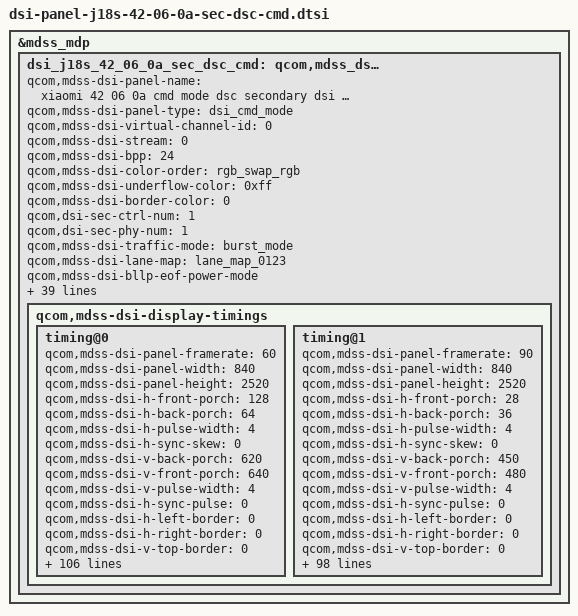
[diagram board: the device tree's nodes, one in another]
&mdss_mdp {
	dsi_j18s_42_06_0a_sec_dsc_cmd: qcom,mdss_dsi_j18s_42_06_0a_sec_dsc_cmd {
		qcom,mdss-dsi-panel-name = "xiaomi 42 06 0a cmd mode dsc secondary dsi panel";
		qcom,mdss-dsi-panel-type = "dsi_cmd_mode";
		qcom,mdss-dsi-virtual-channel-id = <0>;
		qcom,mdss-dsi-stream = <0>;
		qcom,mdss-dsi-bpp = <24>;
		qcom,mdss-dsi-color-order = "rgb_swap_rgb";
		qcom,mdss-dsi-underflow-color = <0xff>;
		qcom,mdss-dsi-border-color = <0>;

		qcom,dsi-sec-ctrl-num = <1>;
		qcom,dsi-sec-phy-num = <1>;

		qcom,mdss-dsi-traffic-mode = "burst_mode";
		qcom,mdss-dsi-lane-map = "lane_map_0123";
		qcom,mdss-dsi-bllp-eof-power-mode;
		qcom,mdss-dsi-bllp-power-mode;
		qcom,mdss-dsi-lane-0-state;
		qcom,mdss-dsi-lane-1-state;
		qcom,mdss-dsi-lane-2-state;
		qcom,mdss-dsi-lane-3-state;
		qcom,mdss-dsi-dma-trigger = "trigger_sw";
		qcom,mdss-dsi-mdp-trigger = "none";
		qcom,mdss-dsi-reset-sequence = <1 1>, <0 1>, <1 15>;
		qcom,mdss-pan-physical-width-dimension = <524>;
		qcom,mdss-pan-physical-height-dimension = <1572>;
		qcom,mdss-dsi-te-pin-select = <1>;
		qcom,mdss-dsi-wr-mem-start = <0x2c>;
		qcom,mdss-dsi-wr-mem-continue = <0x3c>;
		qcom,mdss-dsi-te-dcs-command = <1>;
		qcom,mdss-dsi-te-check-enable;
		qcom,mdss-dsi-te-using-te-pin;
		qcom,mdss-dsi-tx-eot-append;
		qcom,mdss-dsi-lp11-init;

		qcom,mdss-dsi-bl-inverted-dbv;

		qcom,mdss-dsi-panel-hdr-enabled;
		qcom,mdss-dsi-panel-hdr-color-primaries = <14500 15500 32000
			17000 15500 30000 8000 3000>;
		qcom,mdss-dsi-panel-peak-brightness = <4200000>;
		qcom,mdss-dsi-panel-blackness-level = <3230>;

		qcom,bl-update-flag = "delay_until_first_frame";

		qcom,mdss-dsi-display-timings {
			timing@0{
				qcom,mdss-dsi-panel-framerate = <60>;
				qcom,mdss-dsi-panel-width = <840>;
				qcom,mdss-dsi-panel-height = <2520>;
				qcom,mdss-dsi-h-front-porch = <128>;
				qcom,mdss-dsi-h-back-porch = <64>;
				qcom,mdss-dsi-h-pulse-width = <4>;
				qcom,mdss-dsi-h-sync-skew = <0>;
				qcom,mdss-dsi-v-back-porch = <620>;
				qcom,mdss-dsi-v-front-porch = <640>;
				qcom,mdss-dsi-v-pulse-width = <4>;
				qcom,mdss-dsi-h-sync-pulse = <0>;
				qcom,mdss-dsi-h-left-border = <0>;
				qcom,mdss-dsi-h-right-border = <0>;
				qcom,mdss-dsi-v-top-border = <0>;
				qcom,mdss-dsi-v-bottom-border = <0>;
				qcom,mdss-dsi-panel-clockrate = <650000000>;
				qcom,mdss-dsi-panel-jitter = <0x5 0x1>;
				qcom,mdss-mdp-transfer-time-us = <14000>;
				qcom,mdss-dsi-on-command = [
					15 00 00 00 00 00 02 FE 00
					15 00 00 00 00 00 02 FA 01
					15 00 00 00 00 00 02 FE 40
					15 00 00 00 00 00 02 82 34
					15 00 00 00 00 00 02 FE D0
					15 00 00 00 00 00 02 42 81
					15 00 00 00 00 00 02 49 01
					15 00 00 00 00 00 02 FE D2
					15 00 00 00 00 00 02 53 08
					15 00 00 00 00 00 02 72 07
					15 00 00 00 00 00 02 00 11
					15 00 00 00 00 00 02 01 ab
					15 00 00 00 00 00 02 02 30
					15 00 00 00 00 00 02 03 09
					15 00 00 00 00 00 02 04 d8
					15 00 00 00 00 00 02 05 03
					15 00 00 00 00 00 02 06 48
					15 00 00 00 00 00 02 07 02
					15 00 00 00 00 00 02 08 76
					15 00 00 00 00 00 02 09 03
					15 00 00 00 00 00 02 0a 48
					15 00 00 00 00 00 02 0b 02
					15 00 00 00 00 00 02 0c 00
					15 00 00 00 00 00 02 0d 20
					15 00 00 00 00 00 02 0e 49
					15 00 00 00 00 00 02 0f f6
					15 00 00 00 00 00 02 10 00
					15 00 00 00 00 00 02 11 0b
					15 00 00 00 00 00 02 12 0c
					15 00 00 00 00 00 02 13 00
					15 00 00 00 00 00 02 14 28
					15 00 00 00 00 00 02 15 00
					15 00 00 00 00 00 02 16 1b
					15 00 00 00 00 00 02 17 18
					15 00 00 00 00 00 02 18 00
					15 00 00 00 00 00 02 19 10
					15 00 00 00 00 00 02 1a f0
					15 00 00 00 00 00 02 1b 07
					15 00 00 00 00 00 02 1c 10
					15 00 00 00 00 00 02 1d 20
					15 00 00 00 00 00 02 1e 00
					15 00 00 00 00 00 02 1f 06
					15 00 00 00 00 00 02 20 0f
					15 00 00 00 00 00 02 21 0f
					15 00 00 00 00 00 02 22 33
					15 00 00 00 00 00 02 23 0e
					15 00 00 00 00 00 02 24 1c
					15 00 00 00 00 00 02 25 2a
					15 00 00 00 00 00 02 26 38
					15 00 00 00 00 00 02 27 46
					15 00 00 00 00 00 02 28 54
					15 00 00 00 00 00 02 29 62
					15 00 00 00 00 00 02 2a 69
					15 00 00 00 00 00 02 2b 70
					15 00 00 00 00 00 02 2d 77
					15 00 00 00 00 00 02 2f 79
					15 00 00 00 00 00 02 30 7b
					15 00 00 00 00 00 02 31 7d
					15 00 00 00 00 00 02 32 7e
					15 00 00 00 00 00 02 33 01
					15 00 00 00 00 00 02 34 02
					15 00 00 00 00 00 02 35 22
					15 00 00 00 00 00 02 36 00
					15 00 00 00 00 00 02 37 2a
					15 00 00 00 00 00 02 38 40
					15 00 00 00 00 00 02 39 2a
					15 00 00 00 00 00 02 3a be
					15 00 00 00 00 00 02 3b 3a
					15 00 00 00 00 00 02 3d fc
					15 00 00 00 00 00 02 3f 3a
					15 00 00 00 00 00 02 40 fa
					15 00 00 00 00 00 02 41 3a
					15 00 00 00 00 00 02 42 f8
					15 00 00 00 00 00 02 43 3b
					15 00 00 00 00 00 02 44 38
					15 00 00 00 00 00 02 45 3b
					15 00 00 00 00 00 02 46 78
					15 00 00 00 00 00 02 47 3b
					15 00 00 00 00 00 02 48 b6
					15 00 00 00 00 00 02 49 4b
					15 00 00 00 00 00 02 4a f6
					15 00 00 00 00 00 02 4b 4c
					15 00 00 00 00 00 02 4c 34
					15 00 00 00 00 00 02 4d 4c
					15 00 00 00 00 00 02 4e 74
					15 00 00 00 00 00 02 4f 5c
					15 00 00 00 00 00 02 50 74
					15 00 00 00 00 00 02 51 8c
					15 00 00 00 00 00 02 52 f4
					15 00 00 00 00 00 02 86 03
					15 00 00 00 00 00 02 87 48
					15 00 00 00 00 00 02 88 00
					15 00 00 00 00 00 02 89 00
					15 00 00 00 00 00 02 8a 00
					15 00 00 00 00 00 02 8b 00
					15 00 00 00 00 00 02 8c 00
					15 00 00 00 00 00 02 8d 00
					15 01 00 00 00 00 02 8e 80
					15 00 00 00 00 00 02 FE E0
					15 00 00 00 00 00 02 E7 00
					/* switch to 60fps */
					15 00 00 00 00 00 02 FE D0
					/*60fps setting*/
					15 00 00 00 00 00 02 70 81
					15 00 00 00 00 00 02 FE 60
					/*extend pulse off*/
					15 00 00 00 00 00 02 C3 00
					15 00 00 00 00 00 02 FE 74
					/*gamma mapping*/
					15 00 00 00 00 00 02 0E FF
					15 00 00 00 00 00 02 0F 00
					15 00 00 00 00 00 02 10 14
					15 00 00 00 00 00 02 11 14
					15 00 00 00 00 00 02 12 13
					15 00 00 00 00 00 02 13 12
					15 00 00 00 00 00 02 14 11
					15 00 00 00 00 00 02 15 10
					15 00 00 00 00 00 02 16 0F
					15 00 00 00 00 00 02 17 0E
					15 00 00 00 00 00 02 18 0D
					15 00 00 00 00 00 02 19 0C
					/*fix flicker issue after phone power up*/
					15 00 00 00 00 00 02 FE 70
					15 00 00 00 00 00 02 30 FF
					15 00 00 00 00 00 02 31 FF
					15 00 00 00 00 00 02 32 FF
					15 00 00 00 00 00 02 33 FF
					15 00 00 00 00 00 02 34 FF
					15 00 00 00 00 00 02 FE 40
					15 00 00 00 00 00 02 1B 20
					15 00 00 00 00 00 02 1C 02
					15 00 00 00 00 00 02 FE 70
					15 00 00 00 00 00 02 35 03
					/* fix AOD flicker issue*/
					15 00 00 00 00 00 02 FE 40
					15 00 00 00 00 00 02 08 13
					15 00 00 00 00 00 02 09 15
					15 00 00 00 00 00 02 6B 20
					15 00 00 00 00 00 02 3D 52
					/* OSC learning*/
					15 00 00 00 00 00 02 FE D0
					15 00 00 00 00 00 02 8F 00
					15 00 00 00 00 00 02 90 AD
					15 00 00 00 00 00 02 91 01
					15 00 00 00 00 00 02 92 2C
					15 00 00 00 00 00 02 93 00
					15 00 00 00 00 00 02 94 05
					15 00 00 00 00 00 02 95 0C
					15 00 00 00 00 00 02 8C 83
					15 00 00 00 00 00 02 FE 00
					15 00 00 00 00 00 02 5E 01
					15 00 00 00 00 00 02 C2 08
					15 00 00 00 00 00 02 35 00
					39 01 00 00 00 00 03 51 00 00
					05 01 00 00 60 00 02 11 00/* Sleep Out */
					05 01 00 00 00 00 02 29 00];/* Display On */
				qcom,mdss-dsi-off-command = [
					05 01 00 00 22 00 02 28 00
					05 01 00 00 11 00 02 10 00];
				qcom,mdss-dsi-on-command-state = "dsi_lp_mode";
				qcom,mdss-dsi-off-command-state = "dsi_lp_mode";

				qcom,mdss-dsi-timing-switch-command = [
					/* switch to 60fps */
					15 00 00 00 00 00 02 FE D0
					/*60fps setting*/
					15 00 00 00 00 00 02 70 81
					15 00 00 00 00 00 02 FE 60
					/*extend pulse off*/
					15 00 00 00 00 00 02 C3 00
					15 00 00 00 00 00 02 FE 74
					/*gamma mapping*/
					15 00 00 00 00 00 02 0E FF
					15 00 00 00 00 00 02 0F 00
					15 00 00 00 00 00 02 10 14
					15 00 00 00 00 00 02 11 14
					15 00 00 00 00 00 02 12 13
					15 00 00 00 00 00 02 13 12
					15 00 00 00 00 00 02 14 11
					15 00 00 00 00 00 02 15 10
					15 00 00 00 00 00 02 16 0F
					15 00 00 00 00 00 02 17 0E
					15 00 00 00 00 00 02 18 0D
					15 00 00 00 00 00 02 19 0C
					/* OSC learning*/
					15 00 00 00 00 00 02 FE D0
					15 00 00 00 00 00 02 8F 00
					15 00 00 00 00 00 02 90 AD
					15 00 00 00 00 00 02 91 01
					15 00 00 00 00 00 02 92 2C
					15 00 00 00 00 00 02 93 00
					15 00 00 00 00 00 02 94 05
					15 00 00 00 00 00 02 95 0C
					15 00 00 00 00 00 02 8C 83
					15 01 00 00 00 00 02 FE 00];
				qcom,mdss-dsi-timing-switch-command-state = "dsi_lp_mode";

				qcom,mdss-dsi-lp1-command = [
					/*extend pulse off*/
					15 00 00 00 00 00 02 FE 60
					15 00 00 00 00 00 02 C3 00
					/* enter AOD*/
					15 00 00 00 00 00 02 FE 00
					15 00 00 00 00 00 02 39 00
					/* fix AOD flicker issue*/
					15 00 00 00 00 00 02 FE 72
					15 00 00 00 00 00 02 49 40
					15 00 00 00 00 00 02 FE 60
					15 00 00 00 00 00 02 CE 10
					15 00 00 00 00 00 02 E2 10
					15 01 00 00 00 00 02 FE 00];
				qcom,mdss-dsi-lp1-command-state = "dsi_lp_mode";

				qcom,mdss-dsi-nolp-command = [
					/* exit AOD*/
					15 00 00 00 00 00 02 FE 00
					15 00 00 00 00 00 02 38 00
					/* fix AOD flicker issue*/
					15 00 00 00 00 00 02 FE 72
					15 00 00 00 00 00 02 49 00
					15 00 00 00 00 00 02 FE 60
					15 00 00 00 00 00 02 CE 1D
					15 00 00 00 00 00 02 E2 1D
					/* extend pulse off */
					15 00 00 00 00 00 02 C3 00
					/* OSC learning*/
					15 00 00 00 00 00 02 FE D0
					15 00 00 00 00 00 02 8F 00
					15 00 00 00 00 00 02 90 AD
					15 00 00 00 00 00 02 91 01
					15 00 00 00 00 00 02 92 2C
					15 00 00 00 00 00 02 93 00
					15 00 00 00 00 00 02 94 05
					15 00 00 00 00 00 02 95 0C
					15 00 00 00 00 00 02 8C 83
					15 01 00 00 00 00 02 FE 00];
				qcom,mdss-dsi-nolp-command-state = "dsi_lp_mode";

				qcom,compression-mode = "dsc";
				qcom,mdss-dsc-slice-height = <630>;
				qcom,mdss-dsc-slice-width = <840>;
				qcom,mdss-dsc-slice-per-pkt = <2>;
				qcom,mdss-dsc-bit-per-component = <10>;
				qcom,mdss-dsc-bit-per-pixel = <8>;
				qcom,mdss-dsc-block-prediction-enable;
			};
			timing@1{
				qcom,mdss-dsi-panel-framerate = <90>;
				qcom,mdss-dsi-panel-width = <840>;
				qcom,mdss-dsi-panel-height = <2520>;
				qcom,mdss-dsi-h-front-porch = <28>;
				qcom,mdss-dsi-h-back-porch = <36>;
				qcom,mdss-dsi-h-pulse-width = <4>;
				qcom,mdss-dsi-h-sync-skew = <0>;
				qcom,mdss-dsi-v-back-porch = <450>;
				qcom,mdss-dsi-v-front-porch = <480>;
				qcom,mdss-dsi-v-pulse-width = <4>;
				qcom,mdss-dsi-h-sync-pulse = <0>;
				qcom,mdss-dsi-h-left-border = <0>;
				qcom,mdss-dsi-h-right-border = <0>;
				qcom,mdss-dsi-v-top-border = <0>;
				qcom,mdss-dsi-v-bottom-border = <0>;
				qcom,mdss-dsi-panel-clockrate = <650000000>;
				qcom,mdss-dsi-panel-jitter = <0x5 0x1>;
				qcom,mdss-mdp-transfer-time-us = <9500>;
				qcom,mdss-dsi-on-command = [
					15 00 00 00 00 00 02 FE 00
					15 00 00 00 00 00 02 FA 01
					15 00 00 00 00 00 02 FE 40
					15 00 00 00 00 00 02 82 34
					15 00 00 00 00 00 02 FE D0
					15 00 00 00 00 00 02 42 81
					15 00 00 00 00 00 02 49 01
					15 00 00 00 00 00 02 FE D2
					15 00 00 00 00 00 02 53 08
					15 00 00 00 00 00 02 72 07
					15 00 00 00 00 00 02 00 11
					15 00 00 00 00 00 02 01 ab
					15 00 00 00 00 00 02 02 30
					15 00 00 00 00 00 02 03 09
					15 00 00 00 00 00 02 04 d8
					15 00 00 00 00 00 02 05 03
					15 00 00 00 00 00 02 06 48
					15 00 00 00 00 00 02 07 02
					15 00 00 00 00 00 02 08 76
					15 00 00 00 00 00 02 09 03
					15 00 00 00 00 00 02 0a 48
					15 00 00 00 00 00 02 0b 02
					15 00 00 00 00 00 02 0c 00
					15 00 00 00 00 00 02 0d 20
					15 00 00 00 00 00 02 0e 49
					15 00 00 00 00 00 02 0f f6
					15 00 00 00 00 00 02 10 00
					15 00 00 00 00 00 02 11 0b
					15 00 00 00 00 00 02 12 0c
					15 00 00 00 00 00 02 13 00
					15 00 00 00 00 00 02 14 28
					15 00 00 00 00 00 02 15 00
					15 00 00 00 00 00 02 16 1b
					15 00 00 00 00 00 02 17 18
					15 00 00 00 00 00 02 18 00
					15 00 00 00 00 00 02 19 10
					15 00 00 00 00 00 02 1a f0
					15 00 00 00 00 00 02 1b 07
					15 00 00 00 00 00 02 1c 10
					15 00 00 00 00 00 02 1d 20
					15 00 00 00 00 00 02 1e 00
					15 00 00 00 00 00 02 1f 06
					15 00 00 00 00 00 02 20 0f
					15 00 00 00 00 00 02 21 0f
					15 00 00 00 00 00 02 22 33
					15 00 00 00 00 00 02 23 0e
					15 00 00 00 00 00 02 24 1c
					15 00 00 00 00 00 02 25 2a
					15 00 00 00 00 00 02 26 38
					15 00 00 00 00 00 02 27 46
					15 00 00 00 00 00 02 28 54
					15 00 00 00 00 00 02 29 62
					15 00 00 00 00 00 02 2a 69
					15 00 00 00 00 00 02 2b 70
					15 00 00 00 00 00 02 2d 77
					15 00 00 00 00 00 02 2f 79
					15 00 00 00 00 00 02 30 7b
					15 00 00 00 00 00 02 31 7d
					15 00 00 00 00 00 02 32 7e
					15 00 00 00 00 00 02 33 01
					15 00 00 00 00 00 02 34 02
					15 00 00 00 00 00 02 35 22
					15 00 00 00 00 00 02 36 00
					15 00 00 00 00 00 02 37 2a
					15 00 00 00 00 00 02 38 40
					15 00 00 00 00 00 02 39 2a
					15 00 00 00 00 00 02 3a be
					15 00 00 00 00 00 02 3b 3a
					15 00 00 00 00 00 02 3d fc
					15 00 00 00 00 00 02 3f 3a
					15 00 00 00 00 00 02 40 fa
					15 00 00 00 00 00 02 41 3a
					15 00 00 00 00 00 02 42 f8
					15 00 00 00 00 00 02 43 3b
					15 00 00 00 00 00 02 44 38
					15 00 00 00 00 00 02 45 3b
					15 00 00 00 00 00 02 46 78
					15 00 00 00 00 00 02 47 3b
					15 00 00 00 00 00 02 48 b6
					15 00 00 00 00 00 02 49 4b
					15 00 00 00 00 00 02 4a f6
					15 00 00 00 00 00 02 4b 4c
					15 00 00 00 00 00 02 4c 34
					15 00 00 00 00 00 02 4d 4c
					15 00 00 00 00 00 02 4e 74
					15 00 00 00 00 00 02 4f 5c
					15 00 00 00 00 00 02 50 74
					15 00 00 00 00 00 02 51 8c
					15 00 00 00 00 00 02 52 f4
					15 00 00 00 00 00 02 86 03
					15 00 00 00 00 00 02 87 48
					15 00 00 00 00 00 02 88 00
					15 00 00 00 00 00 02 89 00
					15 00 00 00 00 00 02 8a 00
					15 00 00 00 00 00 02 8b 00
					15 00 00 00 00 00 02 8c 00
					15 00 00 00 00 00 02 8d 00
					15 01 00 00 00 00 02 8e 80
					15 00 00 00 00 00 02 FE E0
					15 00 00 00 00 00 02 E7 00
					/*fix flicker issue after phone power up*/
					15 00 00 00 00 00 02 FE 70
					15 00 00 00 00 00 02 30 FF
					15 00 00 00 00 00 02 31 FF
					15 00 00 00 00 00 02 32 FF
					15 00 00 00 00 00 02 33 FF
					15 00 00 00 00 00 02 34 FF
					15 00 00 00 00 00 02 FE 40
					15 00 00 00 00 00 02 1B 20
					15 00 00 00 00 00 02 1C 02
					15 00 00 00 00 00 02 FE 70
					15 00 00 00 00 00 02 35 03
					/* fix AOD flicker issue*/
					15 00 00 00 00 00 02 FE 40
					15 00 00 00 00 00 02 6B 20
					15 00 00 00 00 00 02 3D 52
					15 00 00 00 00 00 02 08 13
					15 00 00 00 00 00 02 09 15
					/* OSC learning*/
					15 00 00 00 00 00 02 FE D0
					15 00 00 00 00 00 02 8F 02
					15 00 00 00 00 00 02 90 49
					15 00 00 00 00 00 02 91 03
					15 00 00 00 00 00 02 92 E8
					15 00 00 00 00 00 02 93 00
					15 00 00 00 00 00 02 94 05
					15 00 00 00 00 00 02 95 05
					15 00 00 00 00 00 02 8C 83
					15 00 00 00 00 00 02 FE 00
					15 00 00 00 00 00 02 5E 01
					15 00 00 00 00 00 02 C2 08
					15 00 00 00 00 00 02 35 00
					39 01 00 00 00 00 03 51 00 00
					05 01 00 00 60 00 02 11 00/* Sleep Out */
					05 01 00 00 00 00 02 29 00];/* Display On */
				qcom,mdss-dsi-off-command = [
					05 01 00 00 22 00 02 28 00
					05 01 00 00 11 00 02 10 00];
				qcom,mdss-dsi-on-command-state = "dsi_lp_mode";
				qcom,mdss-dsi-off-command-state = "dsi_lp_mode";

				qcom,mdss-dsi-timing-switch-command = [
					/* switch to 90fps */
					15 00 00 00 00 00 02 FE D0
					/*90fps setting*/
					15 00 00 00 00 00 02 70 01
					15 00 00 00 00 00 02 FE 74
					/*gamma mapping*/
					15 00 00 00 00 00 02 0E FF
					15 00 00 00 00 00 02 0F 00
					15 00 00 00 00 00 02 10 09
					15 00 00 00 00 00 02 11 09
					15 00 00 00 00 00 02 12 08
					15 00 00 00 00 00 02 13 07
					15 00 00 00 00 00 02 14 06
					15 00 00 00 00 00 02 15 05
					15 00 00 00 00 00 02 16 04
					15 00 00 00 00 00 02 17 03
					15 00 00 00 00 00 02 18 02
					15 00 00 00 00 00 02 19 01
					/* OSC learning*/
					15 00 00 00 00 00 02 FE D0
					15 00 00 00 00 00 02 8F 02
					15 00 00 00 00 00 02 90 49
					15 00 00 00 00 00 02 91 03
					15 00 00 00 00 00 02 92 E8
					15 00 00 00 00 00 02 93 00
					15 00 00 00 00 00 02 94 05
					15 00 00 00 00 00 02 95 05
					15 00 00 00 00 00 02 8C 83
					15 01 00 00 00 00 02 FE 00];
				qcom,mdss-dsi-timing-switch-command-state = "dsi_lp_mode";

				qcom,mdss-dsi-lp1-command = [
					/* switch to 60fps */
					15 00 00 00 00 00 02 FE D0
					15 00 00 00 00 00 02 70 81
					15 00 00 00 00 00 02 FE 60
					15 00 00 00 00 00 02 C3 00
					15 00 00 00 00 00 02 FE 74
					/*gamma mapping*/
					15 00 00 00 00 00 02 0E FF
					15 00 00 00 00 00 02 0F 00
					15 00 00 00 00 00 02 10 14
					15 00 00 00 00 00 02 11 14
					15 00 00 00 00 00 02 12 13
					15 00 00 00 00 00 02 13 12
					15 00 00 00 00 00 02 14 11
					15 00 00 00 00 00 02 15 10
					15 00 00 00 00 00 02 16 0F
					15 00 00 00 00 00 02 17 0E
					15 00 00 00 00 00 02 18 0D
					15 00 00 00 00 00 02 19 0C
					/* enter AOD*/
					15 00 00 00 00 00 02 FE 00
					15 00 00 00 00 00 02 39 00
					/* fix AOD flicker issue*/
					15 00 00 00 00 00 02 FE 72
					15 00 00 00 00 00 02 49 40
					15 00 00 00 00 00 02 FE 60
					15 00 00 00 00 00 02 CE 10
					15 00 00 00 00 00 02 E2 10
					15 01 00 00 00 00 02 FE 00];
				qcom,mdss-dsi-lp1-command-state = "dsi_lp_mode";

				qcom,mdss-dsi-nolp-command = [
					/* exit AOD*/
					15 00 00 00 00 00 02 FE 00
					15 00 00 00 00 00 02 38 00
					/* fix AOD flicker issue*/
					15 00 00 00 00 00 02 FE 72
					15 00 00 00 00 00 02 49 00
					15 00 00 00 00 00 02 FE 60
					15 00 00 00 00 00 02 CE 1D
					15 00 00 00 00 00 02 E2 1D
					/* switch to 90fps */
					15 00 00 00 00 00 02 FE D0
					/*90fps setting*/
					15 00 00 00 00 00 02 70 01
					15 00 00 00 00 00 02 FE 60
					15 00 00 00 00 00 02 C3 08
					15 00 00 00 00 00 02 FE 74
					/*gamma mapping*/
					15 00 00 00 00 00 02 0E FF
					15 00 00 00 00 00 02 0F 00
					15 00 00 00 00 00 02 10 09
					15 00 00 00 00 00 02 11 09
					15 00 00 00 00 00 02 12 08
					15 00 00 00 00 00 02 13 07
					15 00 00 00 00 00 02 14 06
					15 00 00 00 00 00 02 15 05
					15 00 00 00 00 00 02 16 04
					15 00 00 00 00 00 02 17 03
					15 00 00 00 00 00 02 18 02
					15 00 00 00 00 00 02 19 01
					/* OSC learning*/
					15 00 00 00 00 00 02 FE D0
					15 00 00 00 00 00 02 8F 02
					15 00 00 00 00 00 02 90 49
					15 00 00 00 00 00 02 91 03
					15 00 00 00 00 00 02 92 E8
					15 00 00 00 00 00 02 93 00
					15 00 00 00 00 00 02 94 05
					15 00 00 00 00 00 02 95 05
					15 00 00 00 00 00 02 8C 83
					15 01 00 00 00 00 02 FE 00];
				qcom,mdss-dsi-nolp-command-state = "dsi_lp_mode";

				qcom,compression-mode = "dsc";
				qcom,mdss-dsc-slice-height = <630>;
				qcom,mdss-dsc-slice-width = <840>;
				qcom,mdss-dsc-slice-per-pkt = <2>;
				qcom,mdss-dsc-bit-per-component = <10>;
				qcom,mdss-dsc-bit-per-pixel = <8>;
				qcom,mdss-dsc-block-prediction-enable;
			};
		};
	};
};

&dsi_j18s_42_06_0a_sec_dsc_cmd {
	mi,esd-err-irq-gpio = <&tlmm 75 0x2001>;

	mi,aod-nolp-command-enabled;
	mi,aod-bl-51ctl-flag;
	mi,fp-display-on-optimize-flag;
	mi,mdss-dsi-panel-bl-dfps-enabled;
	mi,mdss-dsi-panel-bl-dfps-switch-threshold = <0x3B8>;

	mi,mdss-dsi-panel-bl-demura-enabled;
	mi,mdss-dsi-panel-bl-demura = <10 38 95 285 951 4095>;

	mi,mdss-dsi-panel-dc-type = <0>;
	mi,mdss-dsi-panel-dc-threshold = <0x11D>;
	mi,max-brightness-clone = <8191>;
	mi,panel-on-dimming-delay = <120>;

	qcom,mdss-dsi-display-timings {
		timing@0{
			mi,mdss-dsi-timing-switch-command = [
				/* switch to 60fps */
				15 00 00 00 00 00 02 FE D0
				/*60fps setting*/
				15 00 00 00 00 00 02 70 81
				15 00 00 00 00 00 02 FE 60
				/*extend pulse on*/
				15 00 00 00 00 00 02 C3 08
				15 00 00 00 00 00 02 FE 74
				/*gamma mapping*/
				15 00 00 00 00 00 02 0E FF
				15 00 00 00 00 00 02 0F 00
				15 00 00 00 00 00 02 10 14
				15 00 00 00 00 00 02 11 14
				15 00 00 00 00 00 02 12 13
				15 00 00 00 00 00 02 13 12
				15 00 00 00 00 00 02 14 11
				15 00 00 00 00 00 02 15 10
				15 00 00 00 00 00 02 16 0F
				15 00 00 00 00 00 02 17 0E
				15 00 00 00 00 00 02 18 0D
				15 00 00 00 00 00 02 19 0C
				/* OSC learning*/
				15 00 00 00 00 00 02 FE D0
				15 00 00 00 00 00 02 8F 00
				15 00 00 00 00 00 02 90 AD
				15 00 00 00 00 00 02 91 01
				15 00 00 00 00 00 02 92 2C
				15 00 00 00 00 00 02 93 00
				15 00 00 00 00 00 02 94 05
				15 00 00 00 00 00 02 95 0C
				15 00 00 00 00 00 02 8C 83
				15 01 00 00 00 00 02 FE 00];
			mi,mdss-dsi-timing-switch-command-state = "dsi_lp_mode";

			mi,mdss-dsi-timing-switch-dc-lbm-command = [
				/* switch to 60fps */
				15 00 00 00 00 00 02 FE D0
				15 00 00 00 00 00 02 70 81
				/*gamma mapping*/
				15 00 00 00 00 00 02 FE 74
				15 00 00 00 00 00 02 0E 80
				15 00 00 00 00 00 02 0F 00
				15 00 00 00 00 00 02 10 0D
				15 00 00 00 00 00 02 11 00
				15 00 00 00 00 00 02 12 00
				15 00 00 00 00 00 02 13 00
				15 00 00 00 00 00 02 14 00
				15 00 00 00 00 00 02 15 00
				15 00 00 00 00 00 02 16 00
				15 00 00 00 00 00 02 17 00
				15 00 00 00 00 00 02 18 0D
				15 00 00 00 00 00 02 19 0C
				15 00 00 00 00 00 02 FE 40
				15 00 00 00 00 00 02 46 39
				15 00 00 00 00 00 02 FE 60
				15 00 00 00 00 00 02 C3 00
				/* OSC learning*/
				15 00 00 00 00 00 02 FE D0
				15 00 00 00 00 00 02 8F 00
				15 00 00 00 00 00 02 90 AD
				15 00 00 00 00 00 02 91 01
				15 00 00 00 00 00 02 92 2C
				15 00 00 00 00 00 02 93 00
				15 00 00 00 00 00 02 94 05
				15 00 00 00 00 00 02 95 0C
				15 00 00 00 00 00 02 8C 83
				15 01 00 00 00 00 02 FE 00];
			mi,mdss-dsi-timing-switch-dc-lbm-command-state = "dsi_lp_mode";

			mi,mdss-dsi-timing-switch-dc-hbm-command = [
				/* switch to 60fps */
				15 00 00 00 00 00 02 FE D0
				15 00 00 00 00 00 02 70 81
				/*gamma mapping*/
				15 00 00 00 00 00 02 FE 74
				15 00 00 00 00 00 02 0E 80
				15 00 00 00 00 00 02 0F 00
				15 00 00 00 00 00 02 10 0D
				15 00 00 00 00 00 02 11 00
				15 00 00 00 00 00 02 12 00
				15 00 00 00 00 00 02 13 00
				15 00 00 00 00 00 02 14 00
				15 00 00 00 00 00 02 15 00
				15 00 00 00 00 00 02 16 00
				15 00 00 00 00 00 02 17 00
				15 00 00 00 00 00 02 18 0D
				15 00 00 00 00 00 02 19 0C
				15 00 00 00 00 00 02 FE 40
				15 00 00 00 00 00 02 46 3E
				/* OSC learning*/
				15 00 00 00 00 00 02 FE D0
				15 00 00 00 00 00 02 8F 00
				15 00 00 00 00 00 02 90 AD
				15 00 00 00 00 00 02 91 01
				15 00 00 00 00 00 02 92 2C
				15 00 00 00 00 00 02 93 00
				15 00 00 00 00 00 02 94 05
				15 00 00 00 00 00 02 95 0C
				15 00 00 00 00 00 02 8C 83
				15 01 00 00 00 00 02 FE 00];
			mi,mdss-dsi-timing-switch-dc-hbm-command-state = "dsi_lp_mode";

			mi,mdss-dsi-bl-extpulse-on-command = [
				/*extend pulse on*/
				15 00 00 00 00 00 02 FE 60
				15 00 00 00 00 00 02 C3 08
				15 01 00 00 00 00 02 FE 00];
			mi,mdss-dsi-bl-extpulse-on-command-state = "dsi_lp_mode";

			mi,mdss-dsi-bl-extpulse-off-command = [
				/*extend pulse off*/
				15 00 00 00 00 00 02 FE 60
				15 00 00 00 00 00 02 C3 00
				15 01 00 00 00 00 02 FE 00];
			mi,mdss-dsi-bl-extpulse-off-command-state = "dsi_lp_mode";

			mi,mdss-dsi-vi-lbm-command = [
				/*extend pulse off*/
				15 00 00 00 00 00 02 FE 40
				15 00 00 00 00 00 02 46 39
				15 01 00 00 00 00 02 FE 00];
			mi,mdss-dsi-vi-lbm-command-state = "dsi_lp_mode";

			mi,mdss-dsi-vi-hbm-command = [
				/*extend pulse off*/
				15 00 00 00 00 00 02 FE 40
				15 00 00 00 00 00 02 46 3E
				15 01 00 00 00 00 02 FE 00];
			mi,mdss-dsi-vi-hbm-command-state = "dsi_lp_mode";

			mi,mdss-dsi-dc-on-command = [
				15 00 00 00 00 00 02 FE 74
				15 00 00 00 00 00 02 00 00
				15 00 00 00 00 00 02 01 00
				15 00 00 00 00 00 02 02 00
				15 00 00 00 00 00 02 03 70
				15 00 00 00 00 00 02 04 0F
				15 00 00 00 00 00 02 05 00
				15 00 00 00 00 00 02 06 00
				15 00 00 00 00 00 02 07 00
				15 00 00 00 00 00 02 08 00
				15 00 00 00 00 00 02 09 00
				15 00 00 00 00 00 02 0A 00
				15 00 00 00 00 00 02 0B 00
				15 00 00 00 00 00 02 0C FF
				15 00 00 00 00 00 02 0D FF
				15 00 00 00 00 00 02 0E 80
				15 00 00 00 00 00 02 0F 00
				15 00 00 00 00 00 02 10 0D
				15 00 00 00 00 00 02 11 00
				15 00 00 00 00 00 02 12 00
				15 00 00 00 00 00 02 13 00
				15 00 00 00 00 00 02 14 00
				15 00 00 00 00 00 02 15 00
				15 00 00 00 00 00 02 16 00
				15 00 00 00 00 00 02 17 00
				15 00 00 00 00 00 02 18 0D
				15 00 00 00 00 00 02 19 0C
				15 00 00 00 00 00 02 22 80
				15 00 00 00 00 00 02 43 80
				15 00 00 00 00 00 02 44 00
				15 00 00 00 00 00 02 45 FF
				15 00 00 00 00 00 02 46 FF
				15 00 00 00 00 00 02 47 FF
				15 00 00 00 00 00 02 48 FF
				15 00 00 00 00 00 02 49 FF
				15 00 00 00 00 00 02 4A FF
				15 00 00 00 00 00 02 4B FF
				15 00 00 00 00 00 02 4C FF
				15 00 00 00 00 00 02 4D FF
				15 00 00 00 00 00 02 4E FF
				15 00 00 00 00 00 02 4F FF
				15 00 00 00 00 00 02 50 FF
				15 00 00 00 00 00 02 51 FF
				15 00 00 00 00 00 02 52 FF
				15 00 00 00 00 00 02 53 FF
				15 00 00 00 00 00 02 61 80
				15 00 00 00 00 00 02 FE 20
				15 00 00 00 00 00 02 B8 08
				15 00 00 00 00 00 02 B9 08
				15 00 00 00 00 00 02 BA 08
				15 00 00 00 00 00 02 FE 40
				15 01 00 00 22 00 02 46 39
				15 00 00 00 00 00 02 FE 60
				15 00 00 00 00 00 02 C3 00
				15 01 00 00 00 00 02 FE 00];
			mi,mdss-dsi-dc-on-command-state = "dsi_lp_mode";

			mi,mdss-dsi-dc-on-hbm-command = [
				15 00 00 00 00 00 02 FE 74
				15 00 00 00 00 00 02 00 00
				15 00 00 00 00 00 02 01 00
				15 00 00 00 00 00 02 02 00
				15 00 00 00 00 00 02 03 70
				15 00 00 00 00 00 02 04 0F
				15 00 00 00 00 00 02 05 00
				15 00 00 00 00 00 02 06 00
				15 00 00 00 00 00 02 07 00
				15 00 00 00 00 00 02 08 00
				15 00 00 00 00 00 02 09 00
				15 00 00 00 00 00 02 0A 00
				15 00 00 00 00 00 02 0B 00
				15 00 00 00 00 00 02 0C FF
				15 00 00 00 00 00 02 0D FF
				15 00 00 00 00 00 02 0E 80
				15 00 00 00 00 00 02 0F 00
				15 00 00 00 00 00 02 10 0D
				15 00 00 00 00 00 02 11 00
				15 00 00 00 00 00 02 12 00
				15 00 00 00 00 00 02 13 00
				15 00 00 00 00 00 02 14 00
				15 00 00 00 00 00 02 15 00
				15 00 00 00 00 00 02 16 00
				15 00 00 00 00 00 02 17 00
				15 00 00 00 00 00 02 18 0D
				15 00 00 00 00 00 02 19 0C
				15 00 00 00 00 00 02 22 80
				15 00 00 00 00 00 02 43 80
				15 00 00 00 00 00 02 44 00
				15 00 00 00 00 00 02 45 FF
				15 00 00 00 00 00 02 46 FF
				15 00 00 00 00 00 02 47 FF
				15 00 00 00 00 00 02 48 FF
				15 00 00 00 00 00 02 49 FF
				15 00 00 00 00 00 02 4A FF
				15 00 00 00 00 00 02 4B FF
				15 00 00 00 00 00 02 4C FF
				15 00 00 00 00 00 02 4D FF
				15 00 00 00 00 00 02 4E FF
				15 00 00 00 00 00 02 4F FF
				15 00 00 00 00 00 02 50 FF
				15 00 00 00 00 00 02 51 FF
				15 00 00 00 00 00 02 52 FF
				15 00 00 00 00 00 02 53 FF
				15 01 00 00 00 00 02 61 80
				15 00 00 00 00 00 02 FE 20
				15 00 00 00 00 00 02 B8 08
				15 00 00 00 00 00 02 B9 08
				15 00 00 00 00 00 02 BA 08
				15 00 00 00 00 00 02 FE 40
				15 00 00 00 22 00 02 46 3E
				15 00 00 00 00 00 02 FE 60
				15 00 00 00 00 00 02 C3 00
				15 01 00 00 00 00 02 FE 00];
			mi,mdss-dsi-dc-on-hbm-command-state = "dsi_lp_mode";

			mi,mdss-dsi-dc-off-command = [
				15 00 00 00 00 00 02 FE 74
				15 00 00 00 00 00 02 00 00
				15 00 00 00 00 00 02 01 00
				15 00 00 00 00 00 02 02 11
				15 00 00 00 00 00 02 03 73
				15 00 00 00 00 00 02 04 0F
				15 00 00 00 00 00 02 05 0A
				15 00 00 00 00 00 02 06 26
				15 00 00 00 00 00 02 07 5F
				15 00 00 00 00 00 02 08 BE
				15 00 00 00 00 00 02 09 1D
				15 00 00 00 00 00 02 0A DC
				15 00 00 00 00 00 02 0B B8
				15 00 00 00 00 00 02 0C FF
				15 00 00 00 00 00 02 0D FF
				15 00 00 00 00 00 02 0E FF
				15 00 00 00 00 00 02 0F 00
				15 00 00 00 00 00 02 10 14
				15 00 00 00 00 00 02 11 14
				15 00 00 00 00 00 02 12 13
				15 00 00 00 00 00 02 13 12
				15 00 00 00 00 00 02 14 11
				15 00 00 00 00 00 02 15 10
				15 00 00 00 00 00 02 16 0F
				15 00 00 00 00 00 02 17 0E
				15 00 00 00 00 00 02 18 0D
				15 00 00 00 00 00 02 19 0C
				15 00 00 00 00 00 02 22 FF
				15 00 00 00 00 00 02 43 FF
				15 00 00 00 00 00 02 44 00
				15 00 00 00 00 00 02 45 11
				15 00 00 00 00 00 02 46 11
				15 00 00 00 00 00 02 47 42
				15 00 00 00 00 00 02 48 f7
				15 00 00 00 00 00 02 49 FF
				15 00 00 00 00 00 02 4A 1F
				15 00 00 00 00 00 02 4B 1F
				15 00 00 00 00 00 02 4C 1F
				15 00 00 00 00 00 02 4D 1F
				15 00 00 00 00 00 02 4E C5
				15 00 00 00 00 00 02 4F 6C
				15 00 00 00 00 00 02 50 BB
				15 00 00 00 00 00 02 51 FF
				15 00 00 00 00 00 02 52 FF
				15 00 00 00 00 00 02 53 FF
				15 00 00 00 00 00 02 61 FF
				15 01 00 00 11 00 02 FE 00];
			mi,mdss-dsi-dc-off-command-state = "dsi_lp_mode";

			mi,mdss-dsi-nolp-command = [
				/* exit AOD*/
				15 00 00 00 00 00 02 FE 00
				05 00 00 00 00 00 02 38 00
				/* fix AOD flicker issue*/
				15 00 00 00 00 00 02 FE 72
				15 00 00 00 00 00 02 49 00
				15 00 00 00 00 00 02 FE 60
				15 00 00 00 00 00 02 CE 1D
				15 00 00 00 00 00 02 E2 1D
				/* extend pulse off */
				15 00 00 00 00 00 02 C3 08
				/* OSC learning*/
				15 00 00 00 00 00 02 FE D0
				15 00 00 00 00 00 02 8F 00
				15 00 00 00 00 00 02 90 AD
				15 00 00 00 00 00 02 91 01
				15 00 00 00 00 00 02 92 2C
				15 00 00 00 00 00 02 93 00
				15 00 00 00 00 00 02 94 05
				15 00 00 00 00 00 02 95 0C
				15 00 00 00 00 00 02 8C 83
				15 01 00 00 00 00 02 FE 00];
			mi,mdss-dsi-nolp-command-state = "dsi_lp_mode";

			mi,mdss-dsi-nolp-dc-lbm-command = [
				/* exit AOD*/
				15 00 00 00 00 00 02 FE 00
				05 00 00 00 00 00 02 38 00
				/* fix AOD flicker issue*/
				15 00 00 00 00 00 02 FE 72
				15 00 00 00 00 00 02 49 00
				15 00 00 00 00 00 02 FE 60
				15 00 00 00 00 00 02 CE 1D
				15 00 00 00 00 00 02 E2 1D
				15 00 00 00 00 00 02 FE 40
				15 00 00 00 00 00 02 46 39
				/* OSC learning*/
				15 00 00 00 00 00 02 FE D0
				15 00 00 00 00 00 02 8F 00
				15 00 00 00 00 00 02 90 AD
				15 00 00 00 00 00 02 91 01
				15 00 00 00 00 00 02 92 2C
				15 00 00 00 00 00 02 93 00
				15 00 00 00 00 00 02 94 05
				15 00 00 00 00 00 02 95 0C
				15 00 00 00 00 00 02 8C 83
				15 01 00 00 00 00 02 FE 00];
			mi,mdss-dsi-nolp-dc-lbm-command-state = "dsi_lp_mode";

			mi,mdss-dsi-nolp-dc-hbm-command = [
				/* exit AOD*/
				15 00 00 00 00 00 02 FE 00
				05 00 00 00 00 00 02 38 00
				/* fix AOD flicker issue*/
				15 00 00 00 00 00 02 FE 72
				15 00 00 00 00 00 02 49 00
				15 00 00 00 00 00 02 FE 60
				15 00 00 00 00 00 02 CE 1D
				15 00 00 00 00 00 02 E2 1D
				15 00 00 00 00 00 02 FE 40
				15 00 00 00 00 00 02 46 3E
				/* OSC learning*/
				15 00 00 00 00 00 02 FE D0
				15 00 00 00 00 00 02 8F 00
				15 00 00 00 00 00 02 90 AD
				15 00 00 00 00 00 02 91 01
				15 00 00 00 00 00 02 92 2C
				15 00 00 00 00 00 02 93 00
				15 00 00 00 00 00 02 94 05
				15 00 00 00 00 00 02 95 0C
				15 00 00 00 00 00 02 8C 83
				15 01 00 00 00 00 02 FE 00];
			mi,mdss-dsi-nolp-dc-hbm-command-state = "dsi_lp_mode";

			mi,mdss-dsi-panel-demura-l1-command = [
				15 00 00 00 00 00 02 FE 20
				15 00 00 00 00 00 02 B8 25
				15 00 00 00 00 00 02 B9 25
				15 00 00 00 00 00 02 BA 25
				15 00 00 00 00 00 02 FE 40
				15 00 00 00 00 00 02 46 39
				15 00 00 00 00 00 02 FE 60
				15 00 00 00 00 00 02 C3 08
				15 01 00 00 00 00 02 FE 00];
			mi,mdss-dsi-panel-demura-l1-command-state = "dsi_lp_mode";

			mi,mdss-dsi-panel-demura-l2-command = [
				15 00 00 00 00 00 02 FE 20
				15 00 00 00 00 00 02 B8 12
				15 00 00 00 00 00 02 B9 12
				15 00 00 00 00 00 02 BA 12
				15 00 00 00 00 00 02 FE 40
				15 00 00 00 00 00 02 46 39
				15 00 00 00 00 00 02 FE 60
				15 00 00 00 00 00 02 C3 08
				15 01 00 00 00 00 02 FE 00];
			mi,mdss-dsi-panel-demura-l2-command-state = "dsi_lp_mode";

			mi,mdss-dsi-panel-demura-l3-command = [
				15 00 00 00 00 00 02 FE 20
				15 00 00 00 00 00 02 B8 10
				15 00 00 00 00 00 02 B9 10
				15 00 00 00 00 00 02 BA 10
				15 00 00 00 00 00 02 FE 40
				15 00 00 00 00 00 02 46 39
				15 00 00 00 00 00 02 FE 60
				15 00 00 00 00 00 02 C3 08
				15 01 00 00 00 00 02 FE 00];
			mi,mdss-dsi-panel-demura-l3-command-state = "dsi_lp_mode";

			mi,mdss-dsi-panel-demura-l4-command = [
				15 00 00 00 00 00 02 FE 20
				15 00 00 00 00 00 02 B8 0B
				15 00 00 00 00 00 02 B9 0B
				15 00 00 00 00 00 02 BA 0B
				15 00 00 00 00 00 02 FE 40
				15 00 00 00 00 00 02 46 39
				15 00 00 00 00 00 02 FE 60
				15 00 00 00 00 00 02 C3 08
				15 01 00 00 00 00 02 FE 00];
			mi,mdss-dsi-panel-demura-l4-command-state = "dsi_lp_mode";

			mi,mdss-dsi-panel-demura-l5-command = [
				15 00 00 00 00 00 02 FE 20
				15 00 00 00 00 00 02 B8 0B
				15 00 00 00 00 00 02 B9 0B
				15 00 00 00 00 00 02 BA 0B
				15 00 00 00 00 00 02 FE 40
				15 00 00 00 00 00 02 46 3E
				15 00 00 00 00 00 02 FE 60
				15 00 00 00 00 00 02 C3 08
				15 01 00 00 00 00 02 FE 00];
			mi,mdss-dsi-panel-demura-l5-command-state = "dsi_lp_mode";

			mi,mdss-dsi-panel-demura-l6-command = [
				15 00 00 00 00 00 02 FE 20
				15 00 00 00 00 00 02 B8 08
				15 00 00 00 00 00 02 B9 08
				15 00 00 00 00 00 02 BA 08
				15 00 00 00 00 00 02 FE 40
				15 00 00 00 00 00 02 46 3E
				15 00 00 00 00 00 02 FE 60
				15 00 00 00 00 00 02 C3 00
				15 01 00 00 00 00 02 FE 00];
			mi,mdss-dsi-panel-demura-l6-command-state = "dsi_lp_mode";

			mi,mdss-dsi-dimmingon-command = [15 01 00 00 00 00 02 53 28];
			mi,mdss-dsi-dimmingon-command-state = "dsi_lp_mode";
			mi,mdss-dsi-dimmingoff-command = [15 01 00 00 00 00 02 53 20];
			mi,mdss-dsi-dimmingoff-command-state = "dsi_lp_mode";
		};
		timing@1{
			mi,mdss-dsi-timing-switch-command = [
				/* switch to 90fps */
				15 00 00 00 00 00 02 FE D0
				/*90fps setting*/
				15 00 00 00 00 00 02 70 01
				15 00 00 00 00 00 02 FE 74
				/*gamma mapping*/
				15 00 00 00 00 00 02 0E FF
				15 00 00 00 00 00 02 0F 00
				15 00 00 00 00 00 02 10 09
				15 00 00 00 00 00 02 11 09
				15 00 00 00 00 00 02 12 08
				15 00 00 00 00 00 02 13 07
				15 00 00 00 00 00 02 14 06
				15 00 00 00 00 00 02 15 05
				15 00 00 00 00 00 02 16 04
				15 00 00 00 00 00 02 17 03
				15 00 00 00 00 00 02 18 02
				15 00 00 00 00 00 02 19 01
				/* OSC learning*/
				15 00 00 00 00 00 02 FE D0
				15 00 00 00 00 00 02 8F 02
				15 00 00 00 00 00 02 90 49
				15 00 00 00 00 00 02 91 03
				15 00 00 00 00 00 02 92 E8
				15 00 00 00 00 00 02 93 00
				15 00 00 00 00 00 02 94 05
				15 00 00 00 00 00 02 95 05
				15 00 00 00 00 00 02 8C 83
				15 01 00 00 00 00 02 FE 00];
			mi,mdss-dsi-timing-switch-command-state = "dsi_lp_mode";

			mi,mdss-dsi-timing-switch-dc-lbm-command = [
				/*switch to 90fps*/
				15 00 00 00 00 00 02 FE D0
				15 00 00 00 00 00 02 70 01
				/*gamma mapping*/
				15 00 00 00 00 00 02 FE 74
				15 00 00 00 00 00 02 0E 80
				15 00 00 00 00 00 02 0F 00
				15 00 00 00 00 00 02 10 02
				15 00 00 00 00 00 02 11 00
				15 00 00 00 00 00 02 12 00
				15 00 00 00 00 00 02 13 00
				15 00 00 00 00 00 02 14 00
				15 00 00 00 00 00 02 15 00
				15 00 00 00 00 00 02 16 00
				15 00 00 00 00 00 02 17 00
				15 00 00 00 00 00 02 18 02
				15 00 00 00 00 00 02 19 01
				15 00 00 00 00 00 02 FE 40
				15 00 00 00 00 00 02 46 39
				/* OSC learning*/
				15 00 00 00 00 00 02 FE D0
				15 00 00 00 00 00 02 8F 02
				15 00 00 00 00 00 02 90 49
				15 00 00 00 00 00 02 91 03
				15 00 00 00 00 00 02 92 E8
				15 00 00 00 00 00 02 93 00
				15 00 00 00 00 00 02 94 05
				15 00 00 00 00 00 02 95 05
				15 00 00 00 00 00 02 8C 83
				15 01 00 00 00 00 02 FE 00];
			mi,mdss-dsi-timing-switch-dc-lbm-command-state = "dsi_lp_mode";

			mi,mdss-dsi-timing-switch-dc-hbm-command = [
				/* switch to 90fps */
				15 00 00 00 00 00 02 FE D0
				15 00 00 00 00 00 02 70 01
				/*gamma mapping*/
				15 00 00 00 00 00 02 FE 74
				15 00 00 00 00 00 02 0E 80
				15 00 00 00 00 00 02 0F 00
				15 00 00 00 00 00 02 10 02
				15 00 00 00 00 00 02 11 00
				15 00 00 00 00 00 02 12 00
				15 00 00 00 00 00 02 13 00
				15 00 00 00 00 00 02 14 00
				15 00 00 00 00 00 02 15 00
				15 00 00 00 00 00 02 16 00
				15 00 00 00 00 00 02 17 00
				15 00 00 00 00 00 02 18 02
				15 00 00 00 00 00 02 19 01
				15 00 00 00 00 00 02 FE 40
				15 00 00 00 00 00 02 46 3E
				/* OSC learning*/
				15 00 00 00 00 00 02 FE D0
				15 00 00 00 00 00 02 8F 02
				15 00 00 00 00 00 02 90 49
				15 00 00 00 00 00 02 91 03
				15 00 00 00 00 00 02 92 E8
				15 00 00 00 00 00 02 93 00
				15 00 00 00 00 00 02 94 05
				15 00 00 00 00 00 02 95 05
				15 00 00 00 00 00 02 8C 83
				15 01 00 00 00 00 02 FE 00];
			mi,mdss-dsi-timing-switch-dc-hbm-command-state = "dsi_lp_mode";

			mi,mdss-dsi-dc-on-command = [
				15 00 00 00 00 00 02 FE 74
				15 00 00 00 00 00 02 00 00
				15 00 00 00 00 00 02 01 00
				15 00 00 00 00 00 02 02 00
				15 00 00 00 00 00 02 03 70
				15 00 00 00 00 00 02 04 0F
				15 00 00 00 00 00 02 05 00
				15 00 00 00 00 00 02 06 00
				15 00 00 00 00 00 02 07 00
				15 00 00 00 00 00 02 08 00
				15 00 00 00 00 00 02 09 00
				15 00 00 00 00 00 02 0A 00
				15 00 00 00 00 00 02 0B 00
				15 00 00 00 00 00 02 0C FF
				15 00 00 00 00 00 02 0D FF
				15 00 00 00 00 00 02 0E 80
				15 00 00 00 00 00 02 0F 00
				15 00 00 00 00 00 02 10 02
				15 00 00 00 00 00 02 11 00
				15 00 00 00 00 00 02 12 00
				15 00 00 00 00 00 02 13 00
				15 00 00 00 00 00 02 14 00
				15 00 00 00 00 00 02 15 00
				15 00 00 00 00 00 02 16 00
				15 00 00 00 00 00 02 17 00
				15 00 00 00 00 00 02 18 02
				15 00 00 00 00 00 02 19 01
				15 00 00 00 00 00 02 22 80
				15 00 00 00 00 00 02 43 80
				15 00 00 00 00 00 02 44 00
				15 00 00 00 00 00 02 45 FF
				15 00 00 00 00 00 02 46 FF
				15 00 00 00 00 00 02 47 FF
				15 00 00 00 00 00 02 48 FF
				15 00 00 00 00 00 02 49 FF
				15 00 00 00 00 00 02 4A FF
				15 00 00 00 00 00 02 4B FF
				15 00 00 00 00 00 02 4C FF
				15 00 00 00 00 00 02 4D FF
				15 00 00 00 00 00 02 4E FF
				15 00 00 00 00 00 02 4F FF
				15 00 00 00 00 00 02 50 FF
				15 00 00 00 00 00 02 51 FF
				15 00 00 00 00 00 02 52 FF
				15 00 00 00 00 00 02 53 FF
				15 00 00 00 00 00 02 61 80
				15 00 00 00 00 00 02 FE 20
				15 00 00 00 00 00 02 B8 08
				15 00 00 00 00 00 02 B9 08
				15 00 00 00 00 00 02 BA 08
				15 00 00 00 00 00 02 FE 40
				15 00 00 00 00 00 02 46 39
				15 01 00 00 00 00 02 FE 00];
			mi,mdss-dsi-dc-on-command-state = "dsi_lp_mode";

			mi,mdss-dsi-dc-on-hbm-command = [
				15 00 00 00 00 00 02 FE 74
				15 00 00 00 00 00 02 00 00
				15 00 00 00 00 00 02 01 00
				15 00 00 00 00 00 02 02 00
				15 00 00 00 00 00 02 03 70
				15 00 00 00 00 00 02 04 0F
				15 00 00 00 00 00 02 05 00
				15 00 00 00 00 00 02 06 00
				15 00 00 00 00 00 02 07 00
				15 00 00 00 00 00 02 08 00
				15 00 00 00 00 00 02 09 00
				15 00 00 00 00 00 02 0A 00
				15 00 00 00 00 00 02 0B 00
				15 00 00 00 00 00 02 0C FF
				15 00 00 00 00 00 02 0D FF
				15 00 00 00 00 00 02 0E 80
				15 00 00 00 00 00 02 0F 00
				15 00 00 00 00 00 02 10 02
				15 00 00 00 00 00 02 11 00
				15 00 00 00 00 00 02 12 00
				15 00 00 00 00 00 02 13 00
				15 00 00 00 00 00 02 14 00
				15 00 00 00 00 00 02 15 00
				15 00 00 00 00 00 02 16 00
				15 00 00 00 00 00 02 17 00
				15 00 00 00 00 00 02 18 02
				15 00 00 00 00 00 02 19 01
				15 00 00 00 00 00 02 22 80
				15 00 00 00 00 00 02 43 80
				15 00 00 00 00 00 02 44 00
				15 00 00 00 00 00 02 45 FF
				15 00 00 00 00 00 02 46 FF
				15 00 00 00 00 00 02 47 FF
				15 00 00 00 00 00 02 48 FF
				15 00 00 00 00 00 02 49 FF
				15 00 00 00 00 00 02 4A FF
				15 00 00 00 00 00 02 4B FF
				15 00 00 00 00 00 02 4C FF
				15 00 00 00 00 00 02 4D FF
				15 00 00 00 00 00 02 4E FF
				15 00 00 00 00 00 02 4F FF
				15 00 00 00 00 00 02 50 FF
				15 00 00 00 00 00 02 51 FF
				15 00 00 00 00 00 02 52 FF
				15 00 00 00 00 00 02 53 FF
				15 00 00 00 00 00 02 61 80
				15 00 00 00 00 00 02 FE 20
				15 00 00 00 00 00 02 B8 08
				15 00 00 00 00 00 02 B9 08
				15 00 00 00 00 00 02 BA 08
				15 00 00 00 00 00 02 FE 40
				15 00 00 00 00 00 02 46 3E
				15 01 00 00 00 00 02 FE 00];
			mi,mdss-dsi-dc-on-hbm-command-state = "dsi_lp_mode";

			mi,mdss-dsi-dc-off-command = [
				 15 00 00 00 00 00 02 FE 74
				 15 00 00 00 00 00 02 00 00
				 15 00 00 00 00 00 02 01 00
				 15 00 00 00 00 00 02 02 11
				 15 00 00 00 00 00 02 03 73
				 15 00 00 00 00 00 02 04 0F
				 15 00 00 00 00 00 02 05 0A
				 15 00 00 00 00 00 02 06 26
				 15 00 00 00 00 00 02 07 5F
				 15 00 00 00 00 00 02 08 BE
				 15 00 00 00 00 00 02 09 1D
				 15 00 00 00 00 00 02 0A DC
				 15 00 00 00 00 00 02 0B B8
				 15 00 00 00 00 00 02 0C FF
				 15 00 00 00 00 00 02 0D FF
				 15 00 00 00 00 00 02 0E FF
				 15 00 00 00 00 00 02 0F 00
				 15 00 00 00 00 00 02 10 09
				 15 00 00 00 00 00 02 11 09
				 15 00 00 00 00 00 02 12 08
				 15 00 00 00 00 00 02 13 07
				 15 00 00 00 00 00 02 14 06
				 15 00 00 00 00 00 02 15 05
				 15 00 00 00 00 00 02 16 04
				 15 00 00 00 00 00 02 17 03
				 15 00 00 00 00 00 02 18 02
				 15 00 00 00 00 00 02 19 01
				 15 00 00 00 00 00 02 22 FF
				 15 00 00 00 00 00 02 43 FF
				 15 00 00 00 00 00 02 44 00
				 15 00 00 00 00 00 02 45 11
				 15 00 00 00 00 00 02 46 11
				 15 00 00 00 00 00 02 47 42
				 15 00 00 00 00 00 02 48 F7
				 15 00 00 00 00 00 02 49 FF
				 15 00 00 00 00 00 02 4A 1F
				 15 00 00 00 00 00 02 4B 1F
				 15 00 00 00 00 00 02 4C 1F
				 15 00 00 00 00 00 02 4D 1F
				 15 00 00 00 00 00 02 4E C5
				 15 00 00 00 00 00 02 4F 6C
				 15 00 00 00 00 00 02 50 BB
				 15 00 00 00 00 00 02 51 FF
				 15 00 00 00 00 00 02 52 FF
				 15 00 00 00 00 00 02 53 FF
				 15 00 00 00 00 00 02 61 FF
				 15 01 00 00 00 00 02 FE 00];
			mi,mdss-dsi-dc-off-command-state = "dsi_lp_mode";

			mi,mdss-dsi-vi-lbm-command = [
				/*extend pulse off*/
				15 00 00 00 00 00 02 FE 40
				15 00 00 00 00 00 02 46 39
				15 01 00 00 00 00 02 FE 00];
			mi,mdss-dsi-vi-lbm-command-state = "dsi_lp_mode";

			mi,mdss-dsi-vi-hbm-command = [
				/*extend pulse off*/
				15 00 00 00 00 00 02 FE 40
				15 00 00 00 00 00 02 46 3E
				15 01 00 00 00 00 02 FE 00];
			mi,mdss-dsi-vi-hbm-command-state = "dsi_lp_mode";

			mi,mdss-dsi-nolp-command = [
				/* exit AOD*/
				15 00 00 00 00 00 02 FE 00
				05 00 00 00 00 00 02 38 00
				/* fix AOD flicker issue*/
				15 00 00 00 00 00 02 FE 72
				15 00 00 00 00 00 02 49 00
				15 00 00 00 00 00 02 FE 60
				15 00 00 00 00 00 02 CE 1D
				15 00 00 00 00 00 02 E2 1D
				/* switch to 90fps */
				15 00 00 00 00 00 02 FE D0
				/*90fps setting*/
				15 00 00 00 00 00 02 70 01
				/*extend pulse on*/
				15 00 00 00 00 00 02 FE 60
				15 00 00 00 00 00 02 C3 08
				/*gamma mapping*/
				15 00 00 00 00 00 02 FE 74
				15 00 00 00 00 00 02 0E FF
				15 00 00 00 00 00 02 0F 00
				15 00 00 00 00 00 02 10 09
				15 00 00 00 00 00 02 11 09
				15 00 00 00 00 00 02 12 08
				15 00 00 00 00 00 02 13 07
				15 00 00 00 00 00 02 14 06
				15 00 00 00 00 00 02 15 05
				15 00 00 00 00 00 02 16 04
				15 00 00 00 00 00 02 17 03
				15 00 00 00 00 00 02 18 02
				15 00 00 00 00 00 02 19 01
				/* OSC learning*/
				15 00 00 00 00 00 02 FE D0
				15 00 00 00 00 00 02 8F 02
				15 00 00 00 00 00 02 90 49
				15 00 00 00 00 00 02 91 03
				15 00 00 00 00 00 02 92 E8
				15 00 00 00 00 00 02 93 00
				15 00 00 00 00 00 02 94 05
				15 00 00 00 00 00 02 95 05
				15 00 00 00 00 00 02 8C 83
				15 01 00 00 00 00 02 FE 00];
			mi,mdss-dsi-nolp-command-state = "dsi_lp_mode";

			mi,mdss-dsi-nolp-dc-lbm-command = [
				/* exit AOD*/
				15 00 00 00 00 00 02 FE 00
				05 00 00 00 00 00 02 38 00
				/* fix AOD flicker issue*/
				15 00 00 00 00 00 02 FE 72
				15 00 00 00 00 00 02 49 00
				15 00 00 00 00 00 02 FE 60
				15 00 00 00 00 00 02 CE 1D
				15 00 00 00 00 00 02 E2 1D
				/* switch to 90fps */
				15 00 00 00 00 00 02 FE D0
				/*90fps setting*/
				15 00 00 00 00 00 02 70 01
				/*gamma mapping*/
				15 00 00 00 00 00 02 FE 74
				15 00 00 00 00 00 02 0E 80
				15 00 00 00 00 00 02 0F 00
				15 00 00 00 00 00 02 10 02
				15 00 00 00 00 00 02 11 00
				15 00 00 00 00 00 02 12 00
				15 00 00 00 00 00 02 13 00
				15 00 00 00 00 00 02 14 00
				15 00 00 00 00 00 02 15 00
				15 00 00 00 00 00 02 16 00
				15 00 00 00 00 00 02 17 00
				15 00 00 00 00 00 02 18 02
				15 00 00 00 00 00 02 19 01
				15 00 00 00 00 00 02 FE 40
				15 00 00 00 00 00 02 46 39
				/* OSC learning*/
				15 00 00 00 00 00 02 FE D0
				15 00 00 00 00 00 02 8F 02
				15 00 00 00 00 00 02 90 49
				15 00 00 00 00 00 02 91 03
				15 00 00 00 00 00 02 92 E8
				15 00 00 00 00 00 02 93 00
				15 00 00 00 00 00 02 94 05
				15 00 00 00 00 00 02 95 05
				15 00 00 00 00 00 02 8C 83
				15 01 00 00 00 00 02 FE 00];
			mi,mdss-dsi-nolp-dc-lbm-command-state = "dsi_lp_mode";

			mi,mdss-dsi-nolp-dc-hbm-command = [
				/* exit AOD*/
				15 00 00 00 00 00 02 FE 00
				05 00 00 00 00 00 02 38 00
				/* fix AOD flicker issue*/
				15 00 00 00 00 00 02 FE 72
				15 00 00 00 00 00 02 49 00
				15 00 00 00 00 00 02 FE 60
				15 00 00 00 00 00 02 CE 1D
				15 00 00 00 00 00 02 E2 1D
				/* switch to 90fps */
				15 00 00 00 00 00 02 FE D0
				/*90fps setting*/
				15 00 00 00 00 00 02 70 01
				/*gamma mapping*/
				15 00 00 00 00 00 02 FE 74
				15 00 00 00 00 00 02 0E 80
				15 00 00 00 00 00 02 0F 00
				15 00 00 00 00 00 02 10 02
				15 00 00 00 00 00 02 11 00
				15 00 00 00 00 00 02 12 00
				15 00 00 00 00 00 02 13 00
				15 00 00 00 00 00 02 14 00
				15 00 00 00 00 00 02 15 00
				15 00 00 00 00 00 02 16 00
				15 00 00 00 00 00 02 17 00
				15 00 00 00 00 00 02 18 02
				15 00 00 00 00 00 02 19 01
				15 00 00 00 00 00 02 FE 40
				15 00 00 00 00 00 02 46 3E
				/* OSC learning*/
				15 00 00 00 00 00 02 FE D0
				15 00 00 00 00 00 02 8F 02
				15 00 00 00 00 00 02 90 49
				15 00 00 00 00 00 02 91 03
				15 00 00 00 00 00 02 92 E8
				15 00 00 00 00 00 02 93 00
				15 00 00 00 00 00 02 94 05
				15 00 00 00 00 00 02 95 05
				15 00 00 00 00 00 02 8C 83
				15 01 00 00 00 00 02 FE 00];
			mi,mdss-dsi-nolp-dc-hbm-command-state = "dsi_lp_mode";

			mi,mdss-dsi-panel-demura-l1-command = [
				15 00 00 00 00 00 02 FE 20
				15 00 00 00 00 00 02 B8 30
				15 00 00 00 00 00 02 B9 30
				15 00 00 00 00 00 02 BA 30
				15 00 00 00 00 00 02 FE 40
				15 00 00 00 00 00 02 46 39
				15 00 00 00 00 00 02 FE 60
				15 00 00 00 00 00 02 C3 08
				15 01 00 00 00 00 02 FE 00];
			mi,mdss-dsi-panel-demura-l1-command-state = "dsi_lp_mode";

			mi,mdss-dsi-panel-demura-l2-command = [
				15 00 00 00 00 00 02 FE 20
				15 00 00 00 00 00 02 B8 12
				15 00 00 00 00 00 02 B9 12
				15 00 00 00 00 00 02 BA 12
				15 00 00 00 00 00 02 FE 40
				15 00 00 00 00 00 02 46 39
				15 00 00 00 00 00 02 FE 60
				15 00 00 00 00 00 02 C3 08
				15 01 00 00 00 00 02 FE 00];
			mi,mdss-dsi-panel-demura-l2-command-state = "dsi_lp_mode";

			mi,mdss-dsi-panel-demura-l3-command = [
				15 00 00 00 00 00 02 FE 20
				15 00 00 00 00 00 02 B8 10
				15 00 00 00 00 00 02 B9 10
				15 00 00 00 00 00 02 BA 10
				15 00 00 00 00 00 02 FE 40
				15 00 00 00 00 00 02 46 39
				15 00 00 00 00 00 02 FE 60
				15 00 00 00 00 00 02 C3 08
				15 01 00 00 00 00 02 FE 00];
			mi,mdss-dsi-panel-demura-l3-command-state = "dsi_lp_mode";

			mi,mdss-dsi-panel-demura-l4-command = [
				15 00 00 00 00 00 02 FE 20
				15 00 00 00 00 00 02 B8 0B
				15 00 00 00 00 00 02 B9 0B
				15 00 00 00 00 00 02 BA 0B
				15 00 00 00 00 00 02 FE 40
				15 00 00 00 00 00 02 46 39
				15 00 00 00 00 00 02 FE 60
				15 00 00 00 00 00 02 C3 08
				15 01 00 00 00 00 02 FE 00];
			mi,mdss-dsi-panel-demura-l4-command-state = "dsi_lp_mode";

			mi,mdss-dsi-panel-demura-l5-command = [
				15 00 00 00 00 00 02 FE 20
				15 00 00 00 00 00 02 B8 0B
				15 00 00 00 00 00 02 B9 0B
				15 00 00 00 00 00 02 BA 0B
				15 00 00 00 00 00 02 FE 40
				15 00 00 00 00 00 02 46 3E
				15 00 00 00 00 00 02 FE 60
				15 00 00 00 00 00 02 C3 08
				15 01 00 00 00 00 02 FE 00];
			mi,mdss-dsi-panel-demura-l5-command-state = "dsi_lp_mode";

			mi,mdss-dsi-panel-demura-l6-command = [
				15 00 00 00 00 00 02 FE 20
				15 00 00 00 00 00 02 B8 08
				15 00 00 00 00 00 02 B9 08
				15 00 00 00 00 00 02 BA 08
				15 00 00 00 00 00 02 FE 40
				15 00 00 00 00 00 02 46 3E
				15 00 00 00 00 00 02 FE 60
				15 00 00 00 00 00 02 C3 00
				15 01 00 00 00 00 02 FE 00];
			mi,mdss-dsi-panel-demura-l6-command-state = "dsi_lp_mode";

			mi,mdss-dsi-dimmingon-command = [15 01 00 00 00 00 02 53 28];
			mi,mdss-dsi-dimmingon-command-state = "dsi_lp_mode";
			mi,mdss-dsi-dimmingoff-command = [15 01 00 00 00 00 02 53 20];
			mi,mdss-dsi-dimmingoff-command-state = "dsi_lp_mode";
		};
	};
};

